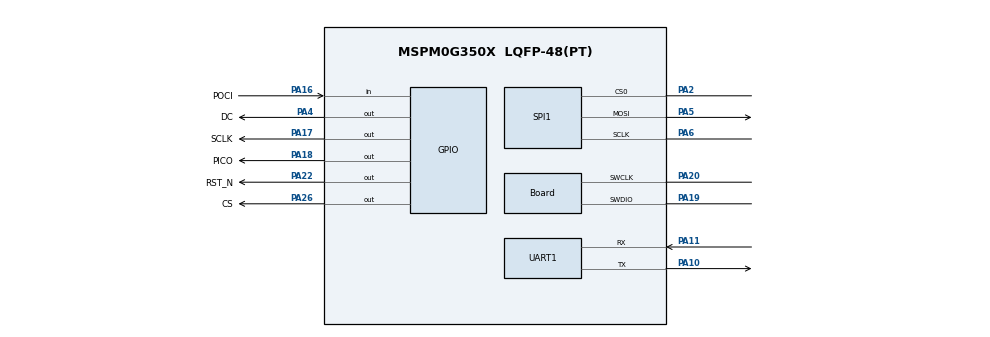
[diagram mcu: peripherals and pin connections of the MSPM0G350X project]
/**
 * @cliArgs --device "MSPM0G350X" --package "LQFP-48(PT)" --part "Default" --product "mspm0_sdk@1.20.01.06"
 * @versions {"tool":"1.18.1+3343"}
 */

/**
 * Import the modules used in this configuration.
 */
const Board         = scripting.addModule("/ti/driverlib/Board");
const GPIO          = scripting.addModule("/ti/driverlib/GPIO", {}, false);
const GPIO1         = GPIO.addInstance();
const GPIO2         = GPIO.addInstance();
const SPI           = scripting.addModule("/ti/driverlib/SPI", {}, false);
const SPI1          = SPI.addInstance();
const SYSCTL        = scripting.addModule("/ti/driverlib/SYSCTL");
const UART          = scripting.addModule("/ti/driverlib/UART", {}, false);
const UART1         = UART.addInstance();
const ProjectConfig = scripting.addModule("/ti/project_config/ProjectConfig");

/**
 * Write custom configuration values to the imported modules.
 */
const divider4       = system.clockTree["PLL_CLK0_DIV"];
divider4.divideValue = 4;

const divider7       = system.clockTree["PLL_PDIV"];
divider7.divideValue = 8;

const gate7  = system.clockTree["MFCLKGATE"];
gate7.enable = true;

const gate8  = system.clockTree["MFPCLKGATE"];
gate8.enable = true;

const multiplier2         = system.clockTree["PLL_QDIV"];
multiplier2.multiplyValue = 40;

const pinFunction4     = system.clockTree["HFXT"];
pinFunction4.inputFreq = 8;

Board.peripheral.$assign          = "DEBUGSS";
Board.peripheral.swclkPin.$assign = "PA20";
Board.peripheral.swdioPin.$assign = "PA19";

GPIO1.$name                         = "OLED";
GPIO1.associatedPins[0].$name       = "DC";
GPIO1.associatedPins[0].pin.$assign = "PA4";

GPIO2.$name                          = "ADS8688";
GPIO2.associatedPins.create(5);
GPIO2.associatedPins[0].$name        = "PICO";
GPIO2.associatedPins[0].initialValue = "SET";
GPIO2.associatedPins[0].pin.$assign  = "PA18";
GPIO2.associatedPins[1].$name        = "POCI";
GPIO2.associatedPins[1].initialValue = "SET";
GPIO2.associatedPins[1].direction    = "INPUT";
GPIO2.associatedPins[1].pin.$assign  = "PA16";
GPIO2.associatedPins[2].$name        = "CS";
GPIO2.associatedPins[2].initialValue = "SET";
GPIO2.associatedPins[2].pin.$assign  = "PA26";
GPIO2.associatedPins[3].$name        = "SCLK";
GPIO2.associatedPins[3].initialValue = "SET";
GPIO2.associatedPins[3].pin.$assign  = "PA17";
GPIO2.associatedPins[4].initialValue = "SET";
GPIO2.associatedPins[4].$name        = "RST_N";
GPIO2.associatedPins[4].pin.$assign  = "PA22";

SPI1.$name                              = "SPI_OLED";
SPI1.enableDMAEvent1                    = false;
SPI1.enableDMAEvent2                    = false;
SPI1.direction                          = "PICO";
SPI1.peripheral.$assign                 = "SPI0";
SPI1.peripheral.sclkPin.$assign         = "PA6";
SPI1.peripheral.mosiPin.$assign         = "PA5";
SPI1.peripheral.cs0Pin.$assign          = "PA2";
SPI1.sclkPinConfig.direction            = scripting.forceWrite("OUTPUT");
SPI1.sclkPinConfig.onlyInternalResistor = scripting.forceWrite(false);
SPI1.sclkPinConfig.passedPeripheralType = scripting.forceWrite("Digital");
SPI1.sclkPinConfig.$name                = "ti_driverlib_gpio_GPIOPinGeneric2";
SPI1.mosiPinConfig.direction            = scripting.forceWrite("OUTPUT");
SPI1.mosiPinConfig.hideOutputInversion  = scripting.forceWrite(false);
SPI1.mosiPinConfig.onlyInternalResistor = scripting.forceWrite(false);
SPI1.mosiPinConfig.passedPeripheralType = scripting.forceWrite("Digital");
SPI1.mosiPinConfig.$name                = "ti_driverlib_gpio_GPIOPinGeneric3";
SPI1.cs0PinConfig.direction             = scripting.forceWrite("OUTPUT");
SPI1.cs0PinConfig.hideOutputInversion   = scripting.forceWrite(false);
SPI1.cs0PinConfig.onlyInternalResistor  = scripting.forceWrite(false);
SPI1.cs0PinConfig.passedPeripheralType  = scripting.forceWrite("Digital");
SPI1.cs0PinConfig.$name                 = "ti_driverlib_gpio_GPIOPinGeneric0";

SYSCTL.MFCLKEn     = true;
SYSCTL.MFPCLKEn    = true;
SYSCTL.clockTreeEn = true;

UART1.$name                    = "UART_0";
UART1.enabledInterrupts        = ["RX"];
UART1.uartClkSrc               = "MFCLK";
UART1.targetBaudRate           = 115200;
UART1.peripheral.$assign       = "UART0";
UART1.peripheral.rxPin.$assign = "PA11";
UART1.peripheral.txPin.$assign = "PA10";
UART1.txPinConfig.$name        = "ti_driverlib_gpio_GPIOPinGeneric6";
UART1.rxPinConfig.$name        = "ti_driverlib_gpio_GPIOPinGeneric7";

ProjectConfig.deviceSpin = "MSPM0G3507";
